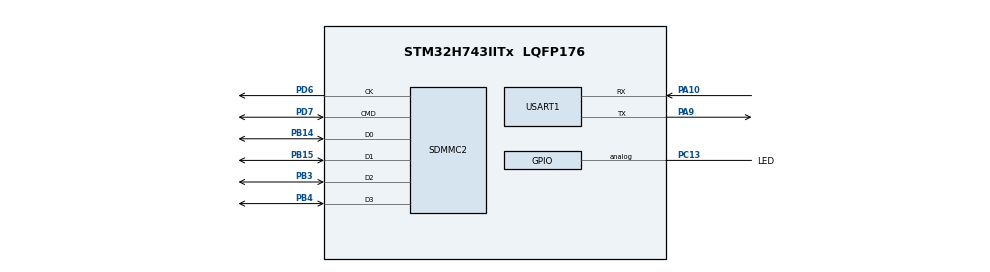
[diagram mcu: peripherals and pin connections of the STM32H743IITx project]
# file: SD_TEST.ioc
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Mcu.Family=STM32H7
Mcu.Name=STM32H743IITx
Mcu.Package=LQFP176
NVIC.PriorityGroup=NVIC_PRIORITYGROUP_4
NVIC.SDMMC2_IRQn=true\:0\:0\:false\:false\:true\:true\:true\:true
PA10.Mode=Asynchronous
PA10.Signal=USART1_RX
PA9.Mode=Asynchronous
PA9.Signal=USART1_TX
PB14.Mode=SD_4_bits_Wide_bus
PB14.Signal=SDMMC2_D0
PB15.Mode=SD_4_bits_Wide_bus
PB15.Signal=SDMMC2_D1
PB3\ (JTDO/TRACESWO).Mode=SD_4_bits_Wide_bus
PB3\ (JTDO/TRACESWO).Signal=SDMMC2_D2
PB4\ (NJTRST).Mode=SD_4_bits_Wide_bus
PB4\ (NJTRST).Signal=SDMMC2_D3
PC13.GPIO_Label=LED
PC13.Signal=GPIO_Analog
PD6.Mode=SD_4_bits_Wide_bus
PD6.Signal=SDMMC2_CK
PD7.Mode=SD_4_bits_Wide_bus
PD7.Signal=SDMMC2_CMD
PH0-OSC_IN\ (PH0).Mode=HSE-External-Oscillator
PH0-OSC_IN\ (PH0).Signal=RCC_OSC_IN
PH1-OSC_OUT\ (PH1).Mode=HSE-External-Oscillator
PH1-OSC_OUT\ (PH1).Signal=RCC_OSC_OUT
ProjectManager.HeapSize=0x800
ProjectManager.StackSize=0x400
ProjectManager.TargetToolchain=MDK-ARM V5.32
RCC.ADCFreq_Value=50390625
RCC.APB1Freq_Value=120000000
RCC.APB2Freq_Value=120000000
RCC.APB3Freq_Value=120000000
RCC.APB4Freq_Value=120000000
RCC.CortexFreq_Value=480000000
RCC.D1PPRE=RCC_APB3_DIV2
RCC.D2PPRE1=RCC_APB1_DIV2
RCC.D2PPRE2=RCC_APB2_DIV2
RCC.D3PPRE=RCC_APB4_DIV2
RCC.DIVM1=5
RCC.DIVN1=192
RCC.DIVQ1=4
RCC.HCLKFreq_Value=240000000
RCC.HPRE=RCC_HCLK_DIV2
RCC.PLLSourceVirtual=RCC_PLLSOURCE_HSE
RCC.PWR_Regulator_Voltage_Scale=PWR_REGULATOR_VOLTAGE_SCALE0
RCC.ProductRev=revV
RCC.SYSCLKFreq_VALUE=480000000
RCC.SYSCLKSource=RCC_SYSCLKSOURCE_PLLCLK
RCC.USBFreq_Value=240000000
SDMMC2.ClockDiv=23
USART1.VirtualMode-Asynchronous=VM_ASYNC
VP_FATFS_VS_SDIO.Mode=SDIO
board=custom

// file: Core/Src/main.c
/* USER CODE BEGIN Header */
/**
  ******************************************************************************
  * @file           : main.c
  * @brief          : Main program body
  ******************************************************************************
  * @attention
  *
  * Copyright (c) 2023 STMicroelectronics.
  * All rights reserved.
  *
  * This software is licensed under terms that can be found in the LICENSE file
  * in the root directory of this software component.
  * If no LICENSE file comes with this software, it is provided AS-IS.
  *
  ******************************************************************************
  */
/* USER CODE END Header */
#include "main.h"
#include "fatfs.h"
#include "sdmmc.h"
#include "usart.h"
#include "gpio.h"

/* USER CODE BEGIN Includes */
#include "stdio.h"
/* USER CODE END Includes */

void SystemClock_Config(void);

/* USER CODE BEGIN 0 */
#ifdef __GNUC__
#define PUTCHAR_PROTOTYPE int __io_putchar(int ch)
#else
#define PUTCHAR_PROTOTYPE int fputc(int ch, FILE *f)
#endif
PUTCHAR_PROTOTYPE
{
    HAL_UART_Transmit(&huart1 , (uint8_t *)&ch, 1, 0xFFFF);
    return ch;
}
/* USER CODE END 0 */

int main(void)
{

  /* MCU Configuration--------------------------------------------------------*/

  /* Reset of all peripherals, Initializes the Flash interface and the Systick. */
  HAL_Init();

  /* Configure the system clock */
  SystemClock_Config();

  /* Initialize all configured peripherals */
  MX_GPIO_Init();
  MX_SDMMC2_SD_Init();
  MX_USART1_UART_Init();
  MX_FATFS_Init();
  /* USER CODE BEGIN 2 */
	sd_card_test();
  /* USER CODE END 2 */

  /* Infinite loop */
  /* USER CODE BEGIN WHILE */
  while (1)
  {
		HAL_Delay(500);
		HAL_GPIO_TogglePin(LED_GPIO_Port,LED_Pin);
		printf("hello world\r\n");
    /* USER CODE END WHILE */

  }
}

void SystemClock_Config(void)
{
  RCC_OscInitTypeDef RCC_OscInitStruct = {0};
  RCC_ClkInitTypeDef RCC_ClkInitStruct = {0};

  /** Supply configuration update enable
  */
  HAL_PWREx_ConfigSupply(PWR_LDO_SUPPLY);

  /** Configure the main internal regulator output voltage
  */
  __HAL_PWR_VOLTAGESCALING_CONFIG(PWR_REGULATOR_VOLTAGE_SCALE1);

  while(!__HAL_PWR_GET_FLAG(PWR_FLAG_VOSRDY)) {}

  __HAL_RCC_SYSCFG_CLK_ENABLE();
  __HAL_PWR_VOLTAGESCALING_CONFIG(PWR_REGULATOR_VOLTAGE_SCALE0);

  while(!__HAL_PWR_GET_FLAG(PWR_FLAG_VOSRDY)) {}

  /** Initializes the RCC Oscillators according to the specified parameters
  * in the RCC_OscInitTypeDef structure.
  */
  RCC_OscInitStruct.OscillatorType = RCC_OSCILLATORTYPE_HSE;
  RCC_OscInitStruct.HSEState = RCC_HSE_ON;
  RCC_OscInitStruct.PLL.PLLState = RCC_PLL_ON;
  RCC_OscInitStruct.PLL.PLLSource = RCC_PLLSOURCE_HSE;
  RCC_OscInitStruct.PLL.PLLM = 5;
  RCC_OscInitStruct.PLL.PLLN = 192;
  RCC_OscInitStruct.PLL.PLLP = 2;
  RCC_OscInitStruct.PLL.PLLQ = 4;
  RCC_OscInitStruct.PLL.PLLR = 2;
  RCC_OscInitStruct.PLL.PLLRGE = RCC_PLL1VCIRANGE_2;
  RCC_OscInitStruct.PLL.PLLVCOSEL = RCC_PLL1VCOWIDE;
  RCC_OscInitStruct.PLL.PLLFRACN = 0;
  if (HAL_RCC_OscConfig(&RCC_OscInitStruct) != HAL_OK)
  {
    Error_Handler();
  }

  /** Initializes the CPU, AHB and APB buses clocks
  */
  RCC_ClkInitStruct.ClockType = RCC_CLOCKTYPE_HCLK|RCC_CLOCKTYPE_SYSCLK
                              |RCC_CLOCKTYPE_PCLK1|RCC_CLOCKTYPE_PCLK2
                              |RCC_CLOCKTYPE_D3PCLK1|RCC_CLOCKTYPE_D1PCLK1;
  RCC_ClkInitStruct.SYSCLKSource = RCC_SYSCLKSOURCE_PLLCLK;
  RCC_ClkInitStruct.SYSCLKDivider = RCC_SYSCLK_DIV1;
  RCC_ClkInitStruct.AHBCLKDivider = RCC_HCLK_DIV2;
  RCC_ClkInitStruct.APB3CLKDivider = RCC_APB3_DIV2;
  RCC_ClkInitStruct.APB1CLKDivider = RCC_APB1_DIV2;
  RCC_ClkInitStruct.APB2CLKDivider = RCC_APB2_DIV2;
  RCC_ClkInitStruct.APB4CLKDivider = RCC_APB4_DIV2;

  if (HAL_RCC_ClockConfig(&RCC_ClkInitStruct, FLASH_LATENCY_4) != HAL_OK)
  {
    Error_Handler();
  }
}

void Error_Handler(void)
{
  __disable_irq();
  while (1)
  {
  }
}
